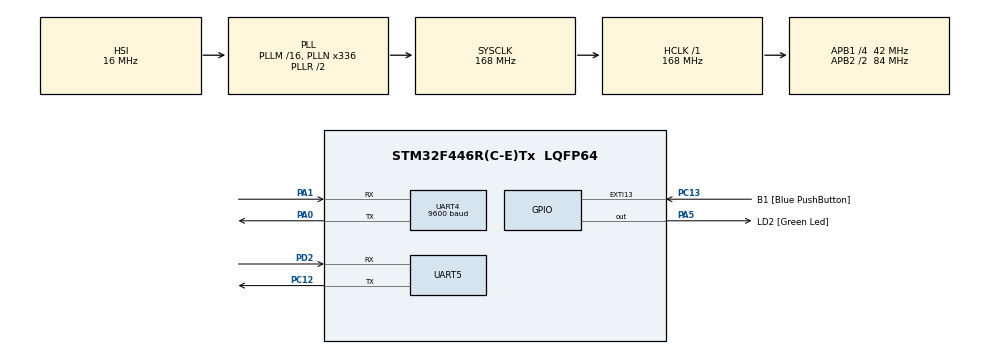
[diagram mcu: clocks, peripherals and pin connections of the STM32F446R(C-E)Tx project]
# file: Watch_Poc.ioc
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Dma.Request0=UART5_TX
Dma.Request1=UART4_RX
Dma.UART4_RX.1.Direction=DMA_PERIPH_TO_MEMORY
Dma.UART4_RX.1.FIFOMode=DMA_FIFOMODE_DISABLE
Dma.UART4_RX.1.Instance=DMA1_Stream2
Dma.UART4_RX.1.MemDataAlignment=DMA_MDATAALIGN_BYTE
Dma.UART4_RX.1.MemInc=DMA_MINC_ENABLE
Dma.UART4_RX.1.Mode=DMA_NORMAL
Dma.UART4_RX.1.PeriphDataAlignment=DMA_PDATAALIGN_BYTE
Dma.UART4_RX.1.PeriphInc=DMA_PINC_DISABLE
Dma.UART4_RX.1.Priority=DMA_PRIORITY_LOW
Dma.UART5_TX.0.Direction=DMA_MEMORY_TO_PERIPH
Dma.UART5_TX.0.FIFOMode=DMA_FIFOMODE_DISABLE
Dma.UART5_TX.0.Instance=DMA1_Stream7
Dma.UART5_TX.0.MemDataAlignment=DMA_MDATAALIGN_BYTE
Dma.UART5_TX.0.MemInc=DMA_MINC_ENABLE
Dma.UART5_TX.0.Mode=DMA_NORMAL
Dma.UART5_TX.0.PeriphDataAlignment=DMA_PDATAALIGN_BYTE
Dma.UART5_TX.0.PeriphInc=DMA_PINC_DISABLE
Dma.UART5_TX.0.Priority=DMA_PRIORITY_LOW
FREERTOS.BinarySemaphores01=writingGpsMutex,Dynamic,NULL,Available
FREERTOS.Tasks01=uiTask,24,128,StartUiTask,Default,NULL,Dynamic,NULL,NULL;GPSTask,40,128,StartGPSTask,Default,NULL,Dynamic,NULL,NULL
FREERTOS.configUSE_NEWLIB_REENTRANT=0
Mcu.Family=STM32F4
Mcu.Name=STM32F446R(C-E)Tx
Mcu.Package=LQFP64
NVIC.DMA1_Stream2_IRQn=true\:5\:0\:false\:false\:true\:true\:false\:true\:true
NVIC.DMA1_Stream7_IRQn=true\:5\:0\:false\:false\:true\:true\:false\:true\:true
NVIC.PriorityGroup=NVIC_PRIORITYGROUP_4
NVIC.TIM1_UP_TIM10_IRQn=true\:15\:0\:false\:false\:true\:false\:false\:true\:true
NVIC.TimeBase=TIM1_UP_TIM10_IRQn
NVIC.TimeBaseIP=TIM1
NVIC.UART4_IRQn=true\:5\:0\:false\:false\:true\:true\:true\:true\:true
PA0-WKUP.Mode=Asynchronous
PA0-WKUP.Signal=UART4_TX
PA1.Mode=Asynchronous
PA1.Signal=UART4_RX
PA13.GPIO_Label=TMS
PA13.Signal=SYS_JTMS-SWDIO
PA14.GPIO_Label=TCK
PA14.Signal=SYS_JTCK-SWCLK
PA2.GPIO_Label=USART_TX
PA2.Signal=USART2_TX
PA3.GPIO_Label=USART_RX
PA3.Signal=USART2_RX
PA5.GPIO_Label=LD2 [Green Led]
PA5.Signal=GPIO_Output
PB3.GPIO_Label=SWO
PB3.Signal=SYS_JTDO-SWO
PC12.Mode=Asynchronous
PC12.Signal=UART5_TX
PC13.GPIO_Label=B1 [Blue PushButton]
PC13.GPIO_ModeDefaultEXTI=GPIO_MODE_IT_FALLING
PC13.Signal=GPXTI13
PC14-OSC32_IN.Signal=RCC_OSC32_IN
PC15-OSC32_OUT.Signal=RCC_OSC32_OUT
PD2.Mode=Asynchronous
PD2.Signal=UART5_RX
PH0-OSC_IN.Signal=RCC_OSC_IN
PH1-OSC_OUT.Signal=RCC_OSC_OUT
ProjectManager.HeapSize=0x200
ProjectManager.StackSize=0x400
ProjectManager.TargetToolchain=STM32CubeIDE
RCC.AHBFreq_Value=168000000
RCC.APB1CLKDivider=RCC_HCLK_DIV4
RCC.APB1Freq_Value=42000000
RCC.APB1TimFreq_Value=84000000
RCC.APB2CLKDivider=RCC_HCLK_DIV2
RCC.APB2Freq_Value=84000000
RCC.APB2TimFreq_Value=168000000
RCC.CortexFreq_Value=168000000
RCC.FLatency-AdvancedSettings=FLASH_LATENCY_5
RCC.HCLKFreq_Value=168000000
RCC.HSE_VALUE=8000000
RCC.HSI_VALUE=16000000
RCC.LSE_VALUE=32768
RCC.PLLN=336
RCC.PLLP=RCC_PLLP_DIV4
RCC.SYSCLKFreq_VALUE=168000000
RCC.SYSCLKSource=RCC_SYSCLKSOURCE_PLLRCLK
RCC.USBFreq_Value=168000000
RCC.VCOOutputFreq_Value=336000000
UART4.BaudRate=9600
UART4.VirtualMode=Asynchronous
UART5.VirtualMode=Asynchronous
VP_FREERTOS_VS_CMSIS_V2.Mode=CMSIS_V2
VP_SYS_VS_tim1.Mode=TIM1
board=NUCLEO-F446RE

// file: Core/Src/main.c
/* USER CODE BEGIN Header */
/**
  ******************************************************************************
  * @file           : main.c
  * @brief          : Main program body
  ******************************************************************************
  * @attention
  *
  * Copyright (c) 2024 STMicroelectronics.
  * All rights reserved.
  *
  * This software is licensed under terms that can be found in the LICENSE file
  * in the root directory of this software component.
  * If no LICENSE file comes with this software, it is provided AS-IS.
  *
  ******************************************************************************
  */
/* USER CODE END Header */
#include "main.h"
#include "cmsis_os.h"
#include "dma.h"
#include "usart.h"
#include "gpio.h"

void SystemClock_Config(void);
void MX_FREERTOS_Init(void);

int main(void)
{

  /* MCU Configuration--------------------------------------------------------*/

  /* Reset of all peripherals, Initializes the Flash interface and the Systick. */
  HAL_Init();

  /* Configure the system clock */
  SystemClock_Config();

  /* Initialize all configured peripherals */
  MX_GPIO_Init();
  MX_DMA_Init();
  MX_UART4_Init();
  MX_UART5_Init();

  /* Init scheduler */
  osKernelInitialize();

  /* Call init function for freertos objects (in cmsis_os2.c) */
  MX_FREERTOS_Init();

  /* Start scheduler */
  osKernelStart();

  /* We should never get here as control is now taken by the scheduler */

  /* Infinite loop */
  while (1)
  {

  }
}

void SystemClock_Config(void)
{
  RCC_OscInitTypeDef RCC_OscInitStruct = {0};
  RCC_ClkInitTypeDef RCC_ClkInitStruct = {0};

  /** Configure the main internal regulator output voltage
  */
  __HAL_RCC_PWR_CLK_ENABLE();
  __HAL_PWR_VOLTAGESCALING_CONFIG(PWR_REGULATOR_VOLTAGE_SCALE1);

  /** Initializes the RCC Oscillators according to the specified parameters
  * in the RCC_OscInitTypeDef structure.
  */
  RCC_OscInitStruct.OscillatorType = RCC_OSCILLATORTYPE_HSI;
  RCC_OscInitStruct.HSIState = RCC_HSI_ON;
  RCC_OscInitStruct.HSICalibrationValue = RCC_HSICALIBRATION_DEFAULT;
  RCC_OscInitStruct.PLL.PLLState = RCC_PLL_ON;
  RCC_OscInitStruct.PLL.PLLSource = RCC_PLLSOURCE_HSI;
  RCC_OscInitStruct.PLL.PLLM = 16;
  RCC_OscInitStruct.PLL.PLLN = 336;
  RCC_OscInitStruct.PLL.PLLP = RCC_PLLP_DIV4;
  RCC_OscInitStruct.PLL.PLLQ = 2;
  RCC_OscInitStruct.PLL.PLLR = 2;
  if (HAL_RCC_OscConfig(&RCC_OscInitStruct) != HAL_OK)
  {
    Error_Handler();
  }

  /** Initializes the CPU, AHB and APB buses clocks
  */
  RCC_ClkInitStruct.ClockType = RCC_CLOCKTYPE_HCLK|RCC_CLOCKTYPE_SYSCLK
                              |RCC_CLOCKTYPE_PCLK1|RCC_CLOCKTYPE_PCLK2;
  RCC_ClkInitStruct.SYSCLKSource = RCC_SYSCLKSOURCE_PLLRCLK;
  RCC_ClkInitStruct.AHBCLKDivider = RCC_SYSCLK_DIV1;
  RCC_ClkInitStruct.APB1CLKDivider = RCC_HCLK_DIV4;
  RCC_ClkInitStruct.APB2CLKDivider = RCC_HCLK_DIV2;

  if (HAL_RCC_ClockConfig(&RCC_ClkInitStruct, FLASH_LATENCY_5) != HAL_OK)
  {
    Error_Handler();
  }
}

void HAL_TIM_PeriodElapsedCallback(TIM_HandleTypeDef *htim)
{
  if (htim->Instance == TIM1) {
    HAL_IncTick();
  }
}

void Error_Handler(void)
{
  __disable_irq();
  while (1)
  {
  }
}

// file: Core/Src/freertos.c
/* USER CODE BEGIN Header */
/**
  ******************************************************************************
  * File Name          : freertos.c
  * Description        : Code for freertos applications
  ******************************************************************************
  * @attention
  *
  * Copyright (c) 2024 STMicroelectronics.
  * All rights reserved.
  *
  * This software is licensed under terms that can be found in the LICENSE file
  * in the root directory of this software component.
  * If no LICENSE file comes with this software, it is provided AS-IS.
  *
  ******************************************************************************
  */
/* USER CODE END Header */

#include "FreeRTOS.h"
#include "task.h"
#include "main.h"
#include "cmsis_os.h"

/* Definitions for uiTask */
osThreadId_t uiTaskHandle;
const osThreadAttr_t uiTask_attributes = {
  .name = "uiTask",
  .stack_size = 128 * 4,
  .priority = (osPriority_t) osPriorityNormal,
};
/* Definitions for GPSTask */
osThreadId_t GPSTaskHandle;
const osThreadAttr_t GPSTask_attributes = {
  .name = "GPSTask",
  .stack_size = 128 * 4,
  .priority = (osPriority_t) osPriorityHigh,
};
/* Definitions for writingGpsMutex */
osSemaphoreId_t writingGpsMutexHandle;
const osSemaphoreAttr_t writingGpsMutex_attributes = {
  .name = "writingGpsMutex"
};

void StartUiTask(void *argument);
void StartGPSTask(void *argument);

void MX_FREERTOS_Init(void); /* (MISRA C 2004 rule 8.1) */

void MX_FREERTOS_Init(void) {

  /* Create the semaphores(s) */
  /* creation of writingGpsMutex */
  writingGpsMutexHandle = osSemaphoreNew(1, 1, &writingGpsMutex_attributes);

  /* Create the thread(s) */
  /* creation of uiTask */
  uiTaskHandle = osThreadNew(StartUiTask, NULL, &uiTask_attributes);

  /* creation of GPSTask */
  GPSTaskHandle = osThreadNew(StartGPSTask, NULL, &GPSTask_attributes);

}

void StartUiTask(void *argument)
{
  /* USER CODE BEGIN StartUiTask */
  /* Infinite loop */
  for(;;)
  {
	  osDelay(500);
	  HAL_GPIO_WritePin(LD2_GPIO_Port, LD2_Pin, 1);
	  osDelay(500);
	  HAL_GPIO_WritePin(LD2_GPIO_Port, LD2_Pin, 0);
  }
  /* USER CODE END StartUiTask */
}

void StartGPSTask(void *argument)
{
  /* USER CODE BEGIN StartGPSTask */
  /* Infinite loop */
  gps_main();
  /* USER CODE END StartGPSTask */
}
